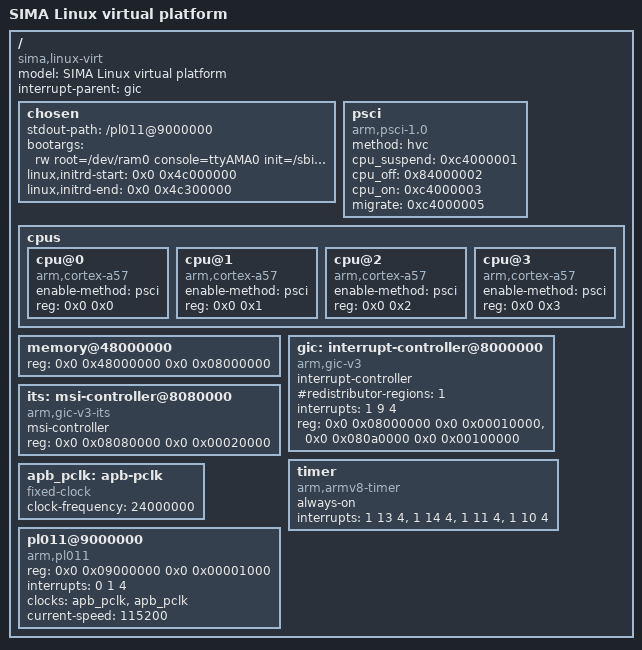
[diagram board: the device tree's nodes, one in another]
/dts-v1/;

/ {
	compatible = "sima,linux-virt";
	model = "SIMA Linux virtual platform";
	#address-cells = <2>;
	#size-cells = <2>;
	interrupt-parent = <&gic>;

	chosen {
		stdout-path = "/pl011@9000000";
		bootargs = "rw root=/dev/ram0 console=ttyAMA0 init=/sbin/init";
		linux,initrd-start = <0x0 0x4c000000>;
		linux,initrd-end = <0x0 0x4c300000>;
	};

	psci {
		compatible = "arm,psci-1.0", "arm,psci-0.2", "arm,psci";
		method = "hvc";
		cpu_suspend = <0xc4000001>;
		cpu_off = <0x84000002>;
		cpu_on = <0xc4000003>;
		migrate = <0xc4000005>;
	};

	cpus {
		#address-cells = <2>;
		#size-cells = <0>;

		cpu@0 {
			device_type = "cpu";
			compatible = "arm,cortex-a57";
			enable-method = "psci";
			reg = <0x0 0x0>;
		};

		cpu@1 {
			device_type = "cpu";
			compatible = "arm,cortex-a57";
			enable-method = "psci";
			reg = <0x0 0x1>;
		};

		cpu@2 {
			device_type = "cpu";
			compatible = "arm,cortex-a57";
			enable-method = "psci";
			reg = <0x0 0x2>;
		};

		cpu@3 {
			device_type = "cpu";
			compatible = "arm,cortex-a57";
			enable-method = "psci";
			reg = <0x0 0x3>;
		};
	};

	memory@48000000 {
		device_type = "memory";
		reg = <0x0 0x48000000 0x0 0x08000000>;
	};

	gic: interrupt-controller@8000000 {
		compatible = "arm,gic-v3";
		#interrupt-cells = <3>;
		#address-cells = <2>;
		#size-cells = <2>;
		interrupt-controller;
		#redistributor-regions = <1>;
		interrupts = <1 9 4>;
		reg = <0x0 0x08000000 0x0 0x00010000>,
		      <0x0 0x080a0000 0x0 0x00100000>;
	};

	its: msi-controller@8080000 {
		compatible = "arm,gic-v3-its";
		msi-controller;
		#msi-cells = <1>;
		reg = <0x0 0x08080000 0x0 0x00020000>;
	};

	timer {
		compatible = "arm,armv8-timer", "arm,armv7-timer";
		always-on;
		interrupts = <1 13 4>,
			     <1 14 4>,
			     <1 11 4>,
			     <1 10 4>;
	};

	apb_pclk: apb-pclk {
		compatible = "fixed-clock";
		#clock-cells = <0>;
		clock-frequency = <24000000>;
	};

	pl011@9000000 {
		compatible = "arm,pl011", "arm,primecell";
		reg = <0x0 0x09000000 0x0 0x00001000>;
		interrupts = <0 1 4>;
		clocks = <&apb_pclk>, <&apb_pclk>;
		clock-names = "uartclk", "apb_pclk";
		current-speed = <115200>;
		status = "okay";
	};
};
